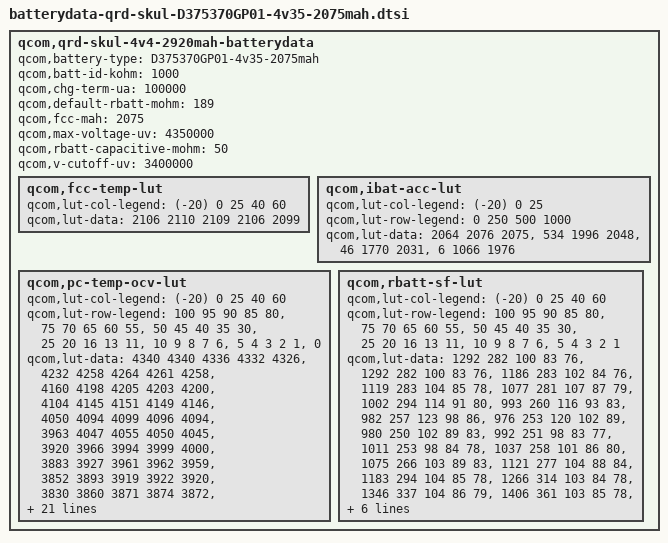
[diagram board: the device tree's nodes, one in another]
/* Copyright (c) 2015, The Linux Foundation. All rights reserved.
 *
 * This program is free software; you can redistribute it and/or modify
 * it under the terms of the GNU General Public License version 2 and
 * only version 2 as published by the Free Software Foundation.
 *
 * This program is distributed in the hope that it will be useful,
 * but WITHOUT ANY WARRANTY; without even the implied warranty of
 * MERCHANTABILITY or FITNESS FOR A PARTICULAR PURPOSE.  See the
 * GNU General Public License for more details.
 */

qcom,qrd-skul-4v4-2920mah-batterydata {
	qcom,battery-type = "D375370GP01-4v35-2075mah";
	qcom,batt-id-kohm = <1000>;
	qcom,chg-term-ua = <100000>;
	qcom,default-rbatt-mohm = <189>;
	qcom,fcc-mah = <2075>;
	qcom,max-voltage-uv = <4350000>;
	qcom,rbatt-capacitive-mohm = <50>;
	qcom,v-cutoff-uv = <3400000>;

	qcom,fcc-temp-lut {
		qcom,lut-col-legend = <(-20) 0 25 40 60>;
		qcom,lut-data = <2106 2110 2109 2106 2099>;
	};

	qcom,ibat-acc-lut {
		qcom,lut-col-legend = <(-20) 0 25>;
		qcom,lut-row-legend = <0 250 500 1000>;
		qcom,lut-data = <2064 2076 2075>,
				<534 1996 2048>,
				<46 1770 2031>,
				<6 1066 1976>;
	};

	qcom,pc-temp-ocv-lut {
		qcom,lut-col-legend = <(-20) 0 25 40 60>;
		qcom,lut-row-legend = <100 95 90 85 80>,
					<75 70 65 60 55>,
					<50 45 40 35 30>,
					<25 20 16 13 11>,
					<10 9 8 7 6>,
					<5 4 3 2 1>,
					<0>;
		qcom,lut-data = <4340 4340 4336 4332 4326>, 
				<4232 4258 4264 4261 4258>, 
				<4160 4198 4205 4203 4200>, 
				<4104 4145 4151 4149 4146>, 
				<4050 4094 4099 4096 4094>, 
				<3963 4047 4055 4050 4045>, 
				<3920 3966 3994 3999 4000>, 
				<3883 3927 3961 3962 3959>, 
				<3852 3893 3919 3922 3920>, 
				<3830 3860 3871 3874 3872>, 
				<3812 3832 3840 3839 3838>, 
				<3796 3810 3816 3816 3816>, 
				<3782 3791 3798 3798 3796>, 
				<3768 3779 3783 3783 3782>, 
				<3754 3768 3770 3768 3764>, 
				<3738 3756 3758 3750 3737>, 
				<3720 3738 3739 3730 3716>, 
				<3703 3721 3718 3710 3696>, 
				<3686 3708 3698 3689 3677>, 
				<3672 3700 3689 3681 3670>, 
				<3663 3696 3688 3680 3668>, 
				<3653 3692 3686 3679 3668>, 
				<3641 3688 3684 3678 3666>, 
				<3626 3681 3681 3674 3662>, 
				<3606 3670 3672 3664 3651>, 
				<3580 3646 3646 3638 3620>, 
				<3542 3604 3601 3591 3572>, 
				<3487 3542 3538 3528 3510>, 
				<3403 3454 3452 3443 3427>, 
				<3266 3314 3316 3306 3296>, 
				<3000 3000 3000 3000 3016>;
	};

	qcom,rbatt-sf-lut {
		qcom,lut-col-legend = <(-20) 0 25 40 60>;
		qcom,lut-row-legend = <100 95 90 85 80>,
					<75 70 65 60 55>,
					<50 45 40 35 30>,
					<25 20 16 13 11>,
					<10 9 8 7 6>,
					<5 4 3 2 1>;
		qcom,lut-data = <1292 282 100 83 76>, 
				<1292 282 100 83 76>, 
				<1186 283 102 84 76>, 
				<1119 283 104 85 78>, 
				<1077 281 107 87 79>, 
				<1002 294 114 91 80>, 
				<993 260 116 93 83>, 
				<982 257 123 98 86>, 
				<976 253 120 102 89>, 
				<980 250 102 89 83>, 
				<992 251 98 83 77>, 
				<1011 253 98 84 78>, 
				<1037 258 101 86 80>, 
				<1075 266 103 89 83>, 
				<1121 277 104 88 84>, 
				<1183 294 104 85 78>, 
				<1266 314 103 84 78>, 
				<1346 337 104 86 79>, 
				<1406 361 103 85 78>, 
				<1396 367 101 83 77>, 
				<1484 381 103 85 79>, 
				<1637 400 105 87 80>, 
				<1814 421 108 89 83>, 
				<2037 448 113 92 85>, 
				<2329 475 117 93 85>, 
				<2733 502 115 90 80>, 
				<3322 539 114 89 80>, 
				<4280 601 120 92 83>, 
				<6148 701 131 98 88>, 
				<12296 1034 164 123 110>;
	};
};
